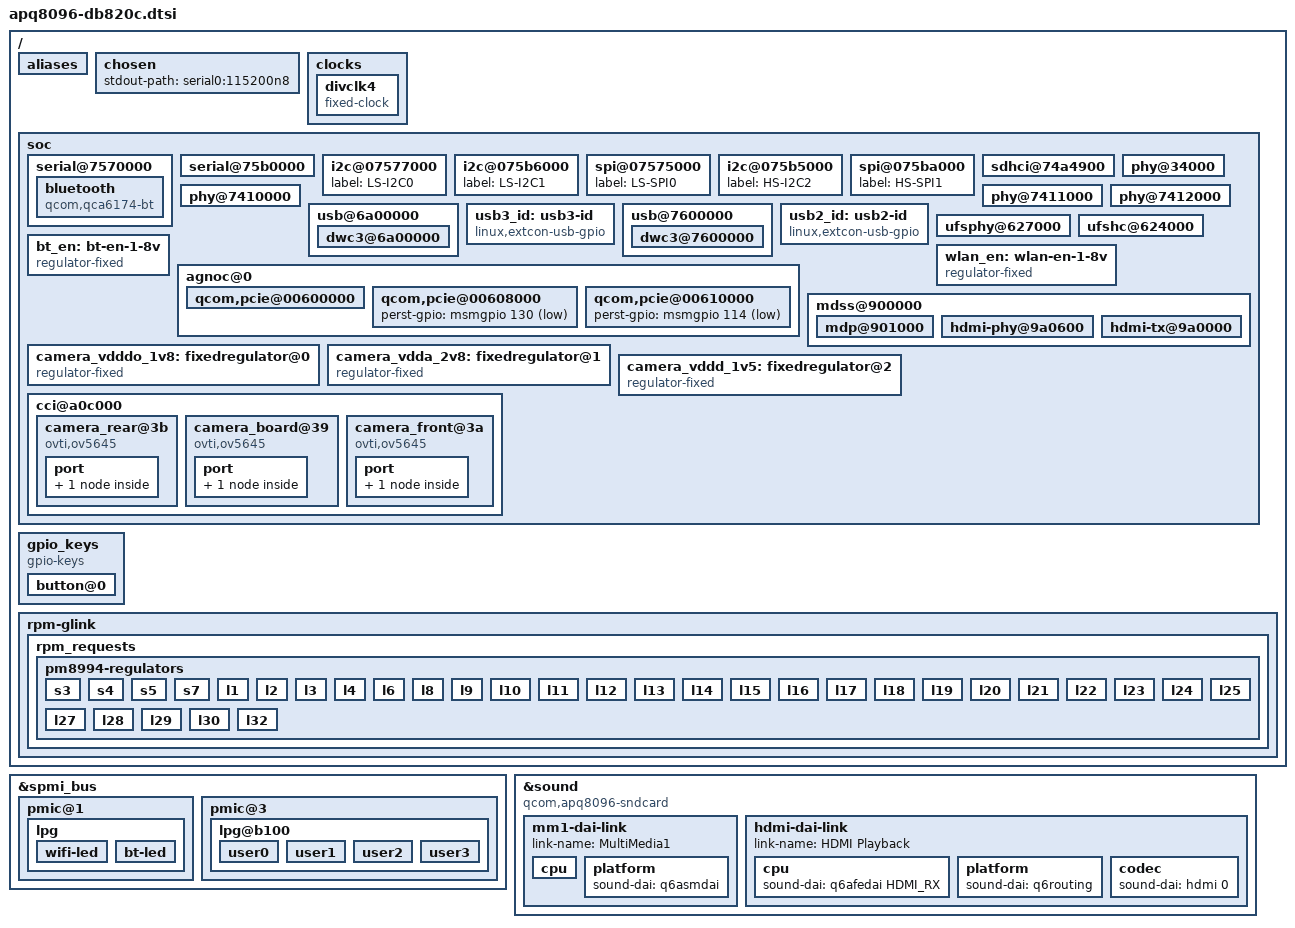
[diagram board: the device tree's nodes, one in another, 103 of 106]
/*
 * Copyright (c) 2014-2016, The Linux Foundation. All rights reserved.
 *
 * This program is free software; you can redistribute it and/or modify
 * it under the terms of the GNU General Public License version 2 and
 * only version 2 as published by the Free Software Foundation.
 *
 * This program is distributed in the hope that it will be useful,
 * but WITHOUT ANY WARRANTY; without even the implied warranty of
 * MERCHANTABILITY or FITNESS FOR A PARTICULAR PURPOSE.  See the
 * GNU General Public License for more details.
 */

#include "msm8996.dtsi"
#include "pm8994.dtsi"
#include "pmi8994.dtsi"
#include "apq8096-db820c-pins.dtsi"
#include "apq8096-db820c-pmic-pins.dtsi"
#include <dt-bindings/input/input.h>
#include <dt-bindings/gpio/gpio.h>
#include <dt-bindings/sound/qcom,q6afe.h>
#include <dt-bindings/sound/qcom,q6asm.h>
/ {
	aliases {
		serial0 = &blsp2_uart1;
		serial1 = &blsp2_uart2;
		serial2 = &blsp1_uart1;
		i2c0	= &blsp1_i2c2;
		i2c1	= &blsp2_i2c1;
		i2c2	= &blsp2_i2c0;
		spi0	= &blsp1_spi0;
		spi1	= &blsp2_spi5;
	};

	chosen {
		stdout-path = "serial0:115200n8";
	};

	clocks {
		divclk4: divclk4 {
			compatible = "fixed-clock";
			#clock-cells = <0>;
			clock-frequency = <32768>;
			clock-output-names = "divclk4";

			pinctrl-names = "default";
			pinctrl-0 = <&divclk4_pin_a>;
		};
	};

	soc {
		serial@7570000 {
			label = "BT-UART";
			status = "okay";
			pinctrl-names = "default", "sleep";
			pinctrl-0 = <&blsp1_uart1_default>;
			pinctrl-1 = <&blsp1_uart1_sleep>;

			bluetooth {
				compatible = "qcom,qca6174-bt";

				/* bt_disable_n gpio */
				enable-gpios = <&pm8994_gpios 19 GPIO_ACTIVE_HIGH>;

				clocks = <&divclk4>;
			};
		};

		serial@75b0000 {
			label = "LS-UART1";
			status = "okay";
			pinctrl-names = "default", "sleep";
			pinctrl-0 = <&blsp2_uart1_2pins_default>;
			pinctrl-1 = <&blsp2_uart1_2pins_sleep>;
		};

//		serial@75b1000 {
//			label = "LS-UART0";
//			status = "okay";
//			pinctrl-names = "default", "sleep";
//			pinctrl-0 = <&blsp2_uart2_4pins_default>;
//			pinctrl-1 = <&blsp2_uart2_4pins_sleep>;
//		};

		i2c@07577000 {
		/* On Low speed expansion */
			label = "LS-I2C0";
			status = "okay";
		};

		i2c@075b6000 {
		/* On Low speed expansion */
			label = "LS-I2C1";
			status = "okay";
		};

		spi@07575000 {
		/* On Low speed expansion */
			label = "LS-SPI0";
			status = "okay";
		};

		i2c@075b5000 {
		/* On High speed expansion */
			label = "HS-I2C2";
			status = "okay";
		};

		spi@075ba000{
		/* On High speed expansion */
			label = "HS-SPI1";
			status = "okay";
		};

		sdhci@74a4900 {
		/* External SD card */
			pinctrl-names = "default", "sleep";
			pinctrl-0 = <&sdc2_clk_on &sdc2_cmd_on &sdc2_data_on &sdc2_cd_on>;
			pinctrl-1 = <&sdc2_clk_off &sdc2_cmd_off &sdc2_data_off &sdc2_cd_off>;
			cd-gpios = <&msmgpio 38 0x1>;
			status = "okay";
		};

		phy@34000 {
			status = "okay";
		};

		phy@7410000 {
			status = "okay";
		};

		phy@7411000 {
			status = "okay";
		};

		phy@7412000 {
			status = "okay";
		};

		usb@6a00000 {
			status = "okay";

			dwc3@6a00000 {
				extcon = <&usb3_id>;
				dr_mode = "otg";
			};
		};

		usb3_id: usb3-id {
			compatible = "linux,extcon-usb-gpio";
			id-gpio = <&pm8994_gpios 22 GPIO_ACTIVE_HIGH>;
			pinctrl-names = "default";
			pinctrl-0 = <&usb3_vbus_det_gpio>;
		};

		usb@7600000 {
			status = "okay";

			dwc3@7600000 {
				extcon = <&usb2_id>;
				dr_mode = "otg";
				maximum-speed = "high-speed";
			};
		};

		usb2_id: usb2-id {
			compatible = "linux,extcon-usb-gpio";
			id-gpio = <&pmi8994_gpios 6 GPIO_ACTIVE_HIGH>;
			pinctrl-names = "default";
			pinctrl-0 = <&usb2_vbus_det_gpio>;
		};

		ufsphy@627000 {
			status = "okay";
		};

		ufshc@624000 {
			status = "okay";
		};

	        bt_en: bt-en-1-8v {
			pinctrl-names = "default";
			pinctrl-0 = <&bt_en_gpios>;
	                compatible = "regulator-fixed";
	                regulator-name = "bt-en-regulator";
	                regulator-min-microvolt = <1800000>;
	                regulator-max-microvolt = <1800000>;

	                /* WLAN card specific delay */
	                startup-delay-us = <70000>;
	                enable-active-high;
	        };

	        wlan_en: wlan-en-1-8v {
			pinctrl-names = "default";
			pinctrl-0 = <&wlan_en_gpios>;
	                compatible = "regulator-fixed";
	                regulator-name = "wlan-en-regulator";
	                regulator-min-microvolt = <1800000>;
	                regulator-max-microvolt = <1800000>;

			gpio = <&pm8994_gpios 8 0>;

	                /* WLAN card specific delay */
	                startup-delay-us = <70000>;
	                enable-active-high;
	        };


		agnoc@0 {
			qcom,pcie@00600000 {
				status = "okay";
				perst-gpio = <&msmgpio 35 GPIO_ACTIVE_LOW>;
				vddpe-3v3-supply = <&wlan_en>;

			};

			qcom,pcie@00608000 {
				status = "okay";
				perst-gpio = <&msmgpio 130 GPIO_ACTIVE_LOW>;
			};

			qcom,pcie@00610000 {
				status = "okay";
				perst-gpio = <&msmgpio 114 GPIO_ACTIVE_LOW>;
			};
		};

		mdss@900000 {
			status = "okay";

			mdp@901000 {
				status = "okay";
			};

			hdmi-phy@9a0600 {
				status = "okay";

				vddio-supply = <&pm8994_l12>;
				vcca-supply = <&pm8994_l28>;
			};

			hdmi-tx@9a0000 {
				status = "okay";

				pinctrl-names = "default", "sleep";
				pinctrl-0 = <&hdmi_hpd_active &hdmi_ddc_active>;
				pinctrl-1 = <&hdmi_hpd_suspend &hdmi_ddc_suspend>;

				core-vdda-supply = <&pm8994_l12>;
				core-vcc-supply = <&pm8994_s4>;
				#sound-dai-cells = <1>;
			};
		};

		camera_vdddo_1v8: fixedregulator@0 {
			compatible = "regulator-fixed";
			regulator-name = "camera_vdddo";
			regulator-min-microvolt = <1800000>;
			regulator-max-microvolt = <1800000>;
			regulator-always-on;
		};

		camera_vdda_2v8: fixedregulator@1 {
			compatible = "regulator-fixed";
			regulator-name = "camera_vdda";
			regulator-min-microvolt = <2800000>;
			regulator-max-microvolt = <2800000>;
			regulator-always-on;
		};

		camera_vddd_1v5: fixedregulator@2 {
			compatible = "regulator-fixed";
			regulator-name = "camera_vddd";
			regulator-min-microvolt = <1500000>;
			regulator-max-microvolt = <1500000>;
			regulator-always-on;
		};

		cci@a0c000 {
			status = "ok";

			camera_rear@3b {
				compatible = "ovti,ov5645";
				reg = <0x3b>;

				enable-gpios = <&msmgpio 26 GPIO_ACTIVE_HIGH>;
				reset-gpios = <&msmgpio 25 GPIO_ACTIVE_LOW>;
				pinctrl-names = "default";
				pinctrl-0 = <&camera_rear_default>;

				clocks = <&mmcc CAMSS_MCLK0_CLK>;
				clock-names = "xclk";
				clock-frequency = <24000000>;

				vdddo-supply = <&camera_vdddo_1v8>;
				vdda-supply = <&camera_vdda_2v8>;
				vddd-supply = <&camera_vddd_1v5>;

				port {
					ov5645_ep: endpoint {
						clock-lanes = <1>;
						data-lanes = <0 2>;
					};
				};
			};

			camera_board@39 {
				compatible = "ovti,ov5645";
				reg = <0x39>;

				enable-gpios = <&msmgpio 98 GPIO_ACTIVE_HIGH>;
				reset-gpios = <&msmgpio 104 GPIO_ACTIVE_LOW>;
				pinctrl-names = "default";
				pinctrl-0 = <&camera_board_default>;

				clocks = <&mmcc CAMSS_MCLK1_CLK>;
				clock-names = "xclk";
				clock-frequency = <24000000>;

				vdddo-supply = <&camera_vdddo_1v8>;
				vdda-supply = <&camera_vdda_2v8>;
				vddd-supply = <&camera_vddd_1v5>;

				port {
					ov5645_2_ep: endpoint {
						clock-lanes = <1>;
						data-lanes = <0 2>;
					};
				};
			};

			camera_front@3a {
				compatible = "ovti,ov5645";
				reg = <0x3a>;

				enable-gpios = <&msmgpio 133 GPIO_ACTIVE_HIGH>;
				reset-gpios = <&msmgpio 23 GPIO_ACTIVE_LOW>;
				pinctrl-names = "default";
				pinctrl-0 = <&camera_front_default>;

				clocks = <&mmcc CAMSS_MCLK2_CLK>;
				clock-names = "xclk";
				clock-frequency = <24000000>;

				vdddo-supply = <&camera_vdddo_1v8>;
				vdda-supply = <&camera_vdda_2v8>;
				vddd-supply = <&camera_vddd_1v5>;

				port {
					ov5645_3_ep: endpoint {
						clock-lanes = <1>;
						data-lanes = <0 2>;
					};
				};
			};
		};
	};


	gpio_keys {
		compatible = "gpio-keys";
		#address-cells = <1>;
		#size-cells = <0>;
		autorepeat;

		pinctrl-names = "default";
		pinctrl-0 = <&volume_up_gpio>;

		button@0 {
			label = "Volume Up";
			linux,code = <KEY_VOLUMEUP>;
			gpios = <&pm8994_gpios 2 GPIO_ACTIVE_LOW>;
		};
	};

	rpm-glink {
		rpm_requests {
			pm8994-regulators {
				vdd_l1-supply = <&pm8994_s3>;
				vdd_l2_l26_l28-supply = <&pm8994_s3>;
				vdd_l3_l11-supply = <&pm8994_s3>;
				vdd_l4_l27_l31-supply = <&pm8994_s3>;
				vdd_l5_l7-supply = <&pm8994_s5>;
				vdd_l14_l15-supply = <&pm8994_s5>;
				vdd_l20_l21-supply = <&pm8994_s5>;
				vdd_l25-supply = <&pm8994_s3>;

				s3 {
					regulator-min-microvolt = <1300000>;
					regulator-max-microvolt = <1300000>;
				};
				s4 {
					regulator-min-microvolt = <1800000>;
					regulator-max-microvolt = <1800000>;
				};
				s5 {
					regulator-min-microvolt = <2150000>;
					regulator-max-microvolt = <2150000>;
				};
				s7 {
					regulator-min-microvolt = <800000>;
					regulator-max-microvolt = <800000>;
				};

				l1 {
					regulator-min-microvolt = <1000000>;
					regulator-max-microvolt = <1000000>;
				};
				l2 {
					regulator-min-microvolt = <1250000>;
					regulator-max-microvolt = <1250000>;
				};
				l3 {
					regulator-min-microvolt = <850000>;
					regulator-max-microvolt = <850000>;
				};
				l4 {
					regulator-min-microvolt = <1225000>;
					regulator-max-microvolt = <1225000>;
				};
				l6 {
					regulator-min-microvolt = <1200000>;
					regulator-max-microvolt = <1200000>;
				};
				l8 {
					regulator-min-microvolt = <1800000>;
					regulator-max-microvolt = <1800000>;
				};
				l9 {
					regulator-min-microvolt = <1800000>;
					regulator-max-microvolt = <1800000>;
				};
				l10 {
					regulator-min-microvolt = <1800000>;
					regulator-max-microvolt = <1800000>;
				};
				l11 {
					regulator-min-microvolt = <1150000>;
					regulator-max-microvolt = <1150000>;
				};
				l12 {
					regulator-min-microvolt = <1800000>;
					regulator-max-microvolt = <1800000>;
				};
				l13 {
					regulator-min-microvolt = <1800000>;
					regulator-max-microvolt = <2950000>;
				};
				l14 {
					regulator-min-microvolt = <1800000>;
					regulator-max-microvolt = <1800000>;
				};
				l15 {
					regulator-min-microvolt = <1800000>;
					regulator-max-microvolt = <1800000>;
				};
				l16 {
					regulator-min-microvolt = <2700000>;
					regulator-max-microvolt = <2700000>;
				};
				l17 {
					regulator-min-microvolt = <2500000>;
					regulator-max-microvolt = <2500000>;
				};
				l18 {
					regulator-min-microvolt = <2700000>;
					regulator-max-microvolt = <2900000>;
				};
				l19 {
					regulator-min-microvolt = <3000000>;
					regulator-max-microvolt = <3000000>;
				};
				l20 {
					regulator-min-microvolt = <2950000>;
					regulator-max-microvolt = <2950000>;
					regulator-allow-set-load;
				};
				l21 {
					regulator-min-microvolt = <2950000>;
					regulator-max-microvolt = <2950000>;
				};
				l22 {
					regulator-min-microvolt = <3300000>;
					regulator-max-microvolt = <3300000>;
				};
				l23 {
					regulator-min-microvolt = <2800000>;
					regulator-max-microvolt = <2800000>;
				};
				l24 {
					regulator-min-microvolt = <3075000>;
					regulator-max-microvolt = <3075000>;
				};
				l25 {
					regulator-min-microvolt = <1200000>;
					regulator-max-microvolt = <1200000>;
					regulator-allow-set-load;
				};
				l27 {
					regulator-min-microvolt = <1000000>;
					regulator-max-microvolt = <1000000>;
				};
				l28 {
					regulator-min-microvolt = <925000>;
					regulator-max-microvolt = <925000>;
					regulator-allow-set-load;
				};
				l29 {
					regulator-min-microvolt = <2800000>;
					regulator-max-microvolt = <2800000>;
				};
				l30 {
					regulator-min-microvolt = <1800000>;
					regulator-max-microvolt = <1800000>;
				};
				l32 {
					regulator-min-microvolt = <1800000>;
					regulator-max-microvolt = <1800000>;
				};
			};
		};
	};
};

&spmi_bus {
	pmic@1 {
		lpg {
			status = "okay";

			qcom,dtest = <1 2>,
				     <2 2>,
				     <0 0>,
				     <0 0>,
				     <0 0>,
				     <0 0>;

			pinctrl-names = "default";
			pinctrl-0 = <&pm8994_mpp2_wifi_led>, <&pm8994_mpp4_bt_led>;

			wifi-led {
				led-sources = <1>;
				linux,default-trigger = "phy0tx";
				default-state = "off";
			};

			bt-led {
				led-sources = <2>;
				linux,default-trigger = "hci0-power";
				default-state = "off";
			};
		};
	};

	pmic@3 {
		lpg@b100 {
			qcom,power-source = <1>;

			qcom,dtest = <0 0>,
				     <0 0>,
				     <0 0>,
				     <4 1>;

			pinctrl-names = "default";
			pinctrl-0 = <&pmi8994_mpp2_userled4>;

			status = "okay";

			user0 {
				led-sources = <2>;

				label = "db820c:green:user0";
				default-state = "on";
				linux,default-trigger = "heartbeat";
			};

			user1 {
				led-sources = <1>;

				label = "db820c:green:user1";
			};

			user2 {
				led-sources = <3>;

				label = "db820c:green:user2";
			};

			user3 {
				led-sources = <4>;

				label = "db820c:green:user3";

				qcom,dtest = <4 1>;
			};
		};
	 };
};
&sound {
	compatible = "qcom,apq8096-sndcard";
	qcom,model = "DB820c";
	qcom,audio-routing =
		"RX_BIAS", "MCLK";
	mm1-dai-link {
		link-name = "MultiMedia1";
		cpu {
			sound-dai = <&q6asmdai  MSM_FRONTEND_DAI_MULTIMEDIA1>;
		};
		platform {
			sound-dai = <&q6asmdai>;
		};
	};

	hdmi-dai-link {
		link-name = "HDMI Playback";
		cpu {
			sound-dai = <&q6afedai HDMI_RX>;
		};

		platform {
			sound-dai = <&q6routing>;
		};

		codec {
			sound-dai = <&hdmi 0>;
		};
	};
};
